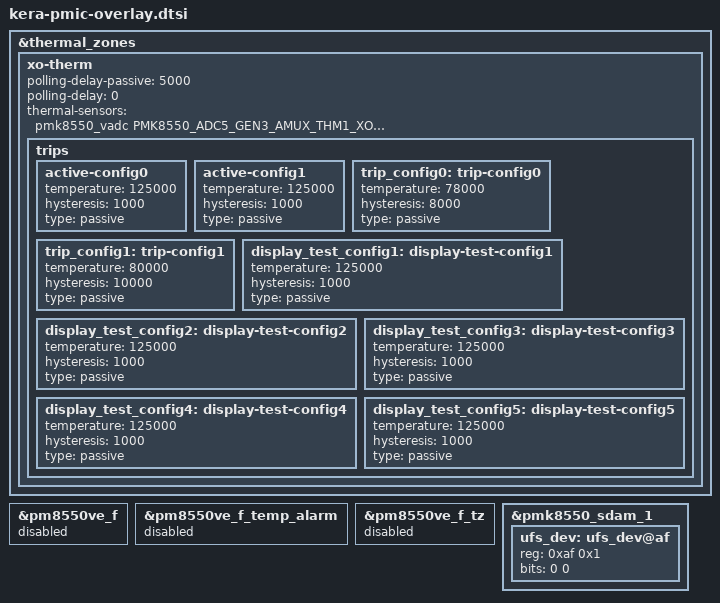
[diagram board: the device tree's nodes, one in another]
// SPDX-License-Identifier: BSD-3-Clause
/*
 * Copyright (c) 2024 Qualcomm Innovation Center, Inc. All rights reserved.
 */

#include "tuna-pmic-overlay.dtsi"

&thermal_zones {
	/delete-node/ sys-therm-0;
	xo-therm {
		polling-delay-passive = <5000>;
		polling-delay = <0>;
		thermal-sensors = <&pmk8550_vadc PMK8550_ADC5_GEN3_AMUX_THM1_XO_THERM_100K_PU>;
		trips {
			active-config0 {
				temperature = <125000>;
				hysteresis = <1000>;
				type = "passive";
			};

			active-config1 {
				temperature = <125000>;
				hysteresis = <1000>;
				type = "passive";
			};

			trip_config0: trip-config0 {
				temperature = <78000>;
				hysteresis = <8000>;
				type = "passive";
			};

			trip_config1: trip-config1 {
				temperature = <80000>;
				hysteresis = <10000>;
				type = "passive";
			};

			display_test_config1: display-test-config1 {
				temperature = <125000>;
				hysteresis = <1000>;
				type = "passive";
			};

			display_test_config2: display-test-config2 {
				temperature = <125000>;
				hysteresis = <1000>;
				type = "passive";
			};

			display_test_config3: display-test-config3 {
				temperature = <125000>;
				hysteresis = <1000>;
				type = "passive";
			};

			display_test_config4: display-test-config4 {
				temperature = <125000>;
				hysteresis = <1000>;
				type = "passive";
			};

			display_test_config5: display-test-config5 {
				temperature = <125000>;
				hysteresis = <1000>;
				type = "passive";
			};
		};
	};
};

&pm8550ve_f {
	status = "disabled";
};

&pm8550ve_f_temp_alarm {
	status = "disabled";
};

&pm8550ve_f_tz {
	status = "disabled";
};

&pmk8550_sdam_1 {
	ufs_dev: ufs_dev@af {
		reg = <0xaf 0x1>;
		bits = <0 0>;
	};
};

